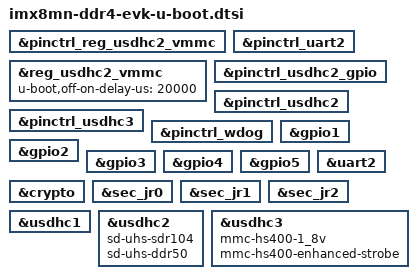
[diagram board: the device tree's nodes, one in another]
// SPDX-License-Identifier: GPL-2.0+
/*
 * Copyright 2019, 2021 NXP
 */

#include "imx8mn-u-boot.dtsi"

&pinctrl_reg_usdhc2_vmmc {
	u-boot,dm-spl;
};

&reg_usdhc2_vmmc {
	u-boot,off-on-delay-us = <20000>;
};

&pinctrl_uart2 {
	u-boot,dm-spl;
};

&pinctrl_usdhc2_gpio {
	u-boot,dm-spl;
};

&pinctrl_usdhc2 {
	u-boot,dm-spl;
};

&pinctrl_usdhc3 {
	u-boot,dm-spl;
};

&pinctrl_wdog {
	u-boot,dm-spl;
};

&gpio1 {
	u-boot,dm-spl;
};

&gpio2 {
	u-boot,dm-spl;
};

&gpio3 {
	u-boot,dm-spl;
};

&gpio4 {
	u-boot,dm-spl;
};

&gpio5 {
	u-boot,dm-spl;
};

&uart2 {
	u-boot,dm-spl;
};

&crypto {
	u-boot,dm-spl;
};

&sec_jr0 {
	u-boot,dm-spl;
};

&sec_jr1 {
	u-boot,dm-spl;
};

&sec_jr2 {
	u-boot,dm-spl;
};

&usdhc1 {
	u-boot,dm-spl;
};

&usdhc2 {
	u-boot,dm-spl;
	sd-uhs-sdr104;
	sd-uhs-ddr50;
};

&usdhc3 {
	u-boot,dm-spl;
	mmc-hs400-1_8v;
	mmc-hs400-enhanced-strobe;
};
